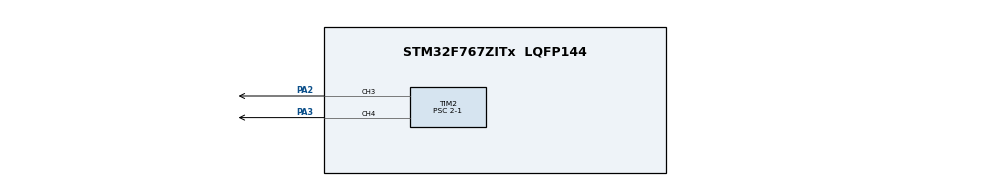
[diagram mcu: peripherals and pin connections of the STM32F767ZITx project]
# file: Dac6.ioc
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Dma.Request0=TIM2_CH2/CH4
Dma.Request1=TIM2_UP/CH3
Dma.TIM2_CH2/CH4.0.Direction=DMA_MEMORY_TO_PERIPH
Dma.TIM2_CH2/CH4.0.FIFOMode=DMA_FIFOMODE_DISABLE
Dma.TIM2_CH2/CH4.0.Instance=DMA1_Stream6
Dma.TIM2_CH2/CH4.0.MemDataAlignment=DMA_MDATAALIGN_WORD
Dma.TIM2_CH2/CH4.0.MemInc=DMA_MINC_ENABLE
Dma.TIM2_CH2/CH4.0.Mode=DMA_CIRCULAR
Dma.TIM2_CH2/CH4.0.PeriphDataAlignment=DMA_PDATAALIGN_WORD
Dma.TIM2_CH2/CH4.0.PeriphInc=DMA_PINC_DISABLE
Dma.TIM2_CH2/CH4.0.Priority=DMA_PRIORITY_LOW
Dma.TIM2_UP/CH3.1.Direction=DMA_MEMORY_TO_PERIPH
Dma.TIM2_UP/CH3.1.FIFOMode=DMA_FIFOMODE_DISABLE
Dma.TIM2_UP/CH3.1.Instance=DMA1_Stream1
Dma.TIM2_UP/CH3.1.MemDataAlignment=DMA_MDATAALIGN_WORD
Dma.TIM2_UP/CH3.1.MemInc=DMA_MINC_ENABLE
Dma.TIM2_UP/CH3.1.Mode=DMA_CIRCULAR
Dma.TIM2_UP/CH3.1.PeriphDataAlignment=DMA_PDATAALIGN_WORD
Dma.TIM2_UP/CH3.1.PeriphInc=DMA_PINC_DISABLE
Dma.TIM2_UP/CH3.1.Priority=DMA_PRIORITY_HIGH
Mcu.Family=STM32F7
Mcu.Name=STM32F767ZITx
Mcu.Package=LQFP144
NVIC.DMA1_Stream1_IRQn=true\:0\:0\:false\:false\:true\:false\:true\:true
NVIC.DMA1_Stream6_IRQn=true\:0\:0\:false\:false\:true\:false\:true\:true
NVIC.PriorityGroup=NVIC_PRIORITYGROUP_4
PA2.Signal=S_TIM2_CH3
PA3.Signal=S_TIM2_CH4
ProjectManager.HeapSize=0x200
ProjectManager.StackSize=0x400
ProjectManager.TargetToolchain=STM32CubeIDE
RCC.HSE_VALUE=25000000
RCC.HSI_VALUE=16000000
RCC.LSE_VALUE=32768
RCC.USBFreq_Value=96000000
RCC.VCOOutputFreq_Value=192000000
SH.S_TIM2_CH3.0=TIM2_CH3,PWM Generation3 CH3
SH.S_TIM2_CH4.0=TIM2_CH4,PWM Generation4 CH4
TIM2.Channel-PWM\ Generation3\ CH3=TIM_CHANNEL_3
TIM2.Channel-PWM\ Generation4\ CH4=TIM_CHANNEL_4
TIM2.Period=190-1
TIM2.Prescaler=2-1
VP_TIM2_VS_ClockSourceINT.Mode=Internal
board=custom

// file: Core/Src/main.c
/* USER CODE BEGIN Header */
/**
  ******************************************************************************
  * @file           : main.c
  * @brief          : Main program body
  ******************************************************************************
  * @attention
  *
  * Copyright (c) 2023 STMicroelectronics.
  * All rights reserved.
  *
  * This software is licensed under terms that can be found in the LICENSE file
  * in the root directory of this software component.
  * If no LICENSE file comes with this software, it is provided AS-IS.
  *
  ******************************************************************************
  */
/* USER CODE END Header */
#include "main.h"

/* USER CODE BEGIN Includes */
uint32_t duty;
/* USER CODE END Includes */

TIM_HandleTypeDef htim2;
DMA_HandleTypeDef hdma_tim2_ch2_ch4;
DMA_HandleTypeDef hdma_tim2_up_ch3;

void SystemClock_Config(void);
static void MX_GPIO_Init(void);
static void MX_TIM2_Init(void);
static void MX_DMA_Init(void);

int main(void)
{

  /* MCU Configuration--------------------------------------------------------*/

  /* Reset of all peripherals, Initializes the Flash interface and the Systick. */
  HAL_Init();

  /* Configure the system clock */
  SystemClock_Config();

  /* Initialize all configured peripherals */
  MX_GPIO_Init();
  MX_TIM2_Init();
  MX_DMA_Init();
  /* USER CODE BEGIN 2 */
  HAL_TIM_PWM_Start_DMA(&htim2, TIM_CHANNEL_3, &duty, 1);
  /* USER CODE END 2 */

  /* Infinite loop */
  while (1)
  {

    /* USER CODE BEGIN 3 */
	  duty++;
	  if(duty>180){duty=0;}
	  HAL_Delay(5);
  }
  /* USER CODE END 3 */
}

void SystemClock_Config(void)
{
  RCC_OscInitTypeDef RCC_OscInitStruct = {0};
  RCC_ClkInitTypeDef RCC_ClkInitStruct = {0};

  /** Configure the main internal regulator output voltage
  */
  __HAL_RCC_PWR_CLK_ENABLE();
  __HAL_PWR_VOLTAGESCALING_CONFIG(PWR_REGULATOR_VOLTAGE_SCALE3);

  /** Initializes the RCC Oscillators according to the specified parameters
  * in the RCC_OscInitTypeDef structure.
  */
  RCC_OscInitStruct.OscillatorType = RCC_OSCILLATORTYPE_HSI;
  RCC_OscInitStruct.HSIState = RCC_HSI_ON;
  RCC_OscInitStruct.HSICalibrationValue = RCC_HSICALIBRATION_DEFAULT;
  RCC_OscInitStruct.PLL.PLLState = RCC_PLL_NONE;
  if (HAL_RCC_OscConfig(&RCC_OscInitStruct) != HAL_OK)
  {
    Error_Handler();
  }

  /** Initializes the CPU, AHB and APB buses clocks
  */
  RCC_ClkInitStruct.ClockType = RCC_CLOCKTYPE_HCLK|RCC_CLOCKTYPE_SYSCLK
                              |RCC_CLOCKTYPE_PCLK1|RCC_CLOCKTYPE_PCLK2;
  RCC_ClkInitStruct.SYSCLKSource = RCC_SYSCLKSOURCE_HSI;
  RCC_ClkInitStruct.AHBCLKDivider = RCC_SYSCLK_DIV1;
  RCC_ClkInitStruct.APB1CLKDivider = RCC_HCLK_DIV1;
  RCC_ClkInitStruct.APB2CLKDivider = RCC_HCLK_DIV1;

  if (HAL_RCC_ClockConfig(&RCC_ClkInitStruct, FLASH_LATENCY_0) != HAL_OK)
  {
    Error_Handler();
  }
}

static void MX_TIM2_Init(void)
{

  TIM_ClockConfigTypeDef sClockSourceConfig = {0};
  TIM_MasterConfigTypeDef sMasterConfig = {0};
  TIM_OC_InitTypeDef sConfigOC = {0};

  htim2.Instance = TIM2;
  htim2.Init.Prescaler = 2-1;
  htim2.Init.CounterMode = TIM_COUNTERMODE_UP;
  htim2.Init.Period = 190-1;
  htim2.Init.ClockDivision = TIM_CLOCKDIVISION_DIV1;
  htim2.Init.AutoReloadPreload = TIM_AUTORELOAD_PRELOAD_DISABLE;
  if (HAL_TIM_Base_Init(&htim2) != HAL_OK)
  {
    Error_Handler();
  }
  sClockSourceConfig.ClockSource = TIM_CLOCKSOURCE_INTERNAL;
  if (HAL_TIM_ConfigClockSource(&htim2, &sClockSourceConfig) != HAL_OK)
  {
    Error_Handler();
  }
  if (HAL_TIM_PWM_Init(&htim2) != HAL_OK)
  {
    Error_Handler();
  }
  sMasterConfig.MasterOutputTrigger = TIM_TRGO_RESET;
  sMasterConfig.MasterSlaveMode = TIM_MASTERSLAVEMODE_DISABLE;
  if (HAL_TIMEx_MasterConfigSynchronization(&htim2, &sMasterConfig) != HAL_OK)
  {
    Error_Handler();
  }
  sConfigOC.OCMode = TIM_OCMODE_PWM1;
  sConfigOC.Pulse = 0;
  sConfigOC.OCPolarity = TIM_OCPOLARITY_HIGH;
  sConfigOC.OCFastMode = TIM_OCFAST_DISABLE;
  if (HAL_TIM_PWM_ConfigChannel(&htim2, &sConfigOC, TIM_CHANNEL_3) != HAL_OK)
  {
    Error_Handler();
  }
  if (HAL_TIM_PWM_ConfigChannel(&htim2, &sConfigOC, TIM_CHANNEL_4) != HAL_OK)
  {
    Error_Handler();
  }
  HAL_TIM_MspPostInit(&htim2);

}

static void MX_DMA_Init(void)
{

  /* DMA controller clock enable */
  __HAL_RCC_DMA1_CLK_ENABLE();

  /* DMA interrupt init */
  /* DMA1_Stream1_IRQn interrupt configuration */
  HAL_NVIC_SetPriority(DMA1_Stream1_IRQn, 0, 0);
  HAL_NVIC_EnableIRQ(DMA1_Stream1_IRQn);
  /* DMA1_Stream6_IRQn interrupt configuration */
  HAL_NVIC_SetPriority(DMA1_Stream6_IRQn, 0, 0);
  HAL_NVIC_EnableIRQ(DMA1_Stream6_IRQn);

}

static void MX_GPIO_Init(void)
{

  /* GPIO Ports Clock Enable */
  __HAL_RCC_GPIOA_CLK_ENABLE();

}

void Error_Handler(void)
{
  __disable_irq();
  while (1)
  {
  }
}
